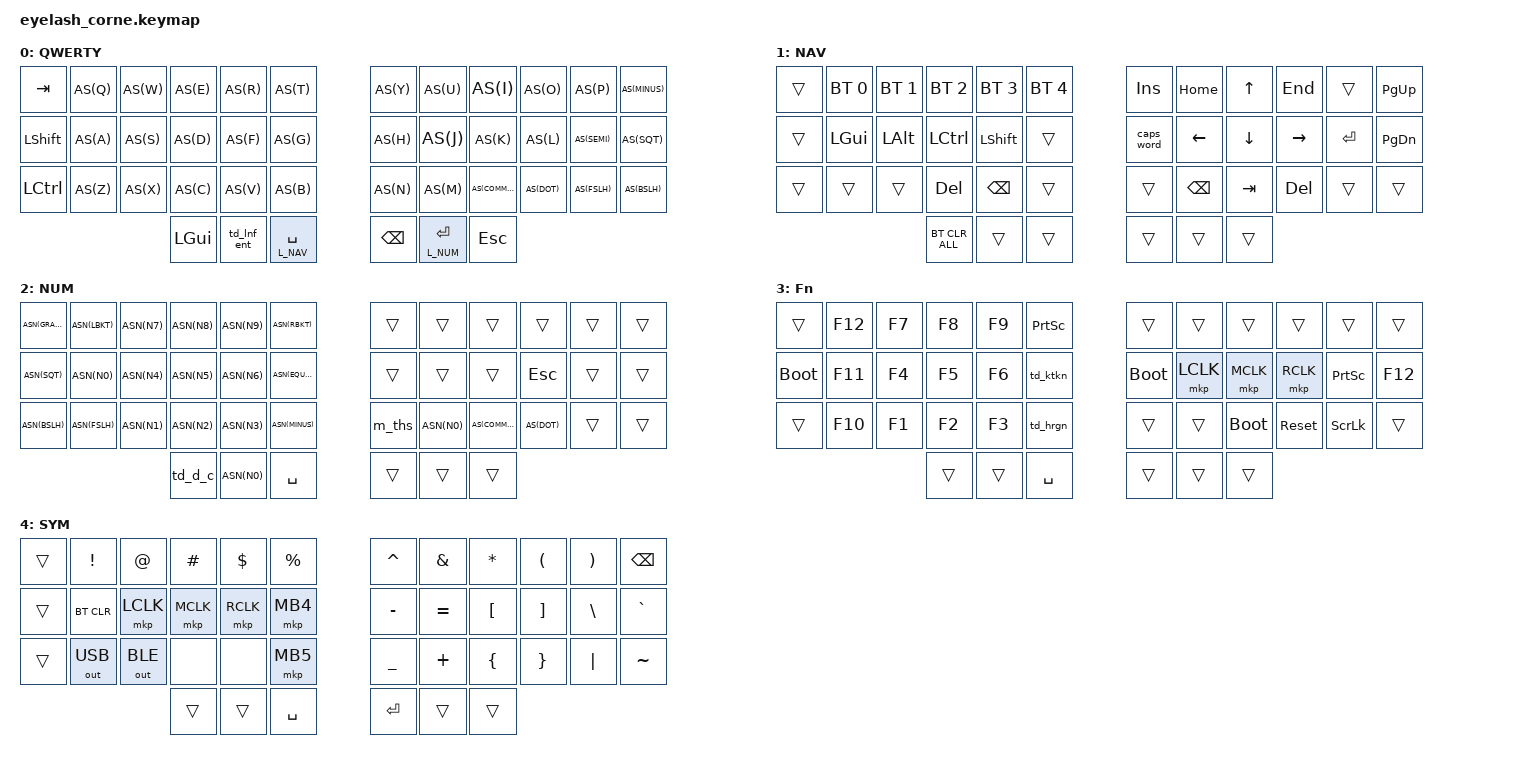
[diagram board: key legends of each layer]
#define ZMK_POINTING_DEFAULT_MOVE_VAL 1200  // 600
#define ZMK_POINTING_DEFAULT_SCRL_VAL 25   // 10

#include <input/processors.dtsi>
#include <zephyr/dt-bindings/input/input-event-codes.h>
#include <behaviors.dtsi>
#include <behaviors/runtime-sensor-rotate.dtsi>
#include <dt-bindings/zmk/bt.h>
#include <dt-bindings/zmk/keys.h>
#include <dt-bindings/zmk/outputs.h>
#include <dt-bindings/zmk/pointing.h>
#include <dt-bindings/zmk/rgb.h>

&soft_off { hold-time-ms = <2000>; };

// ------------ LAYERS -----------
#define L_DEFAULT 0
#define L_NAV 1
#define L_NUM 2
#define L_FUN 3

// -------- LAYER TOGGLES --------
#define LNAV_SPC &lt L_NAV SPACE
#define LNF_ENT &td_lnf_ent
#define LNUM_ENT &lt L_NUM ENTER

#define AS(keycode) &as LS(keycode) keycode     // Autoshift Macro
#define ASN(keycode) &as_ni LS(keycode) keycode   

// ------------ OTHERS -----------
#define MIC_TOGG &kp F24
#define CW_TOGG &caps_word

#define OUTUSB  &out OUT_USB
#define OUTBLE  &out OUT_BLE
#define BTCLR   &bt BT_CLR
#define BT_CLR_A &bt BT_CLR_ALL
#define BT_SEL_0 &bt BT_SEL 0
#define BT_SEL_1 &bt BT_SEL 1
#define BT_SEL_2 &bt BT_SEL 2
#define BT_SEL_3 &bt BT_SEL 3
#define BT_SEL_4 &bt BT_SEL 4

#define STD_UNL  &studio_unlock
#define BOOTLDER &bootloader
#define SYSRESET &sys_reset

/ {
    behaviors {
        as: auto_shift {
            compatible = "zmk,behavior-hold-tap";
            #binding-cells = <2>;
            tapping-term-ms = <250>;
            quick-tap-ms = <0>;
            require-prior-idle-ms = <50>;
            flavor = "tap-preferred";
            bindings = <&kp>, <&kp>;
        };
        // No prior idle is useful for preventing typos, but key presses
        // done after layer triggers have no need of prior idle.
        as_ni: auto_shift_no_idle {
            compatible = "zmk,behavior-hold-tap";
            #binding-cells = <2>;
            tapping-term-ms = <250>;
            quick-tap-ms = <0>;
            flavor = "tap-preferred";
            bindings = <&kp>, <&kp>;
        };
        lh: layer_tap_hold_preffered {
            compatible = "zmk,behavior-hold-tap";
            #binding-cells = <2>;
            tapping-term-ms = <200>;
            flavor = "hold-preferred";
            bindings = <&mo>, <&kp>;
        };
        td_d_c: tap_dance_dot_comma {
            compatible = "zmk,behavior-tap-dance";
            #binding-cells = <0>;
            tapping-term-ms = <250>;
            bindings = <&kp DOT>, <&kp COMMA>;
        };
        td_hrgn: tap_dance_hiragana {
            compatible = "zmk,behavior-tap-dance";
            #binding-cells = <0>;
            tapping-term-ms = <250>;
            bindings = <&kp LC(CAPS)>, <&kp LS(CAPS)>;
        };
        td_ktkn: tap_dance_katakana {
            compatible = "zmk,behavior-tap-dance";
            #binding-cells = <0>;
            tapping-term-ms = <250>;
            bindings = <&kp LA(CAPS)>, <&kp LS(CAPS)>;
        };
        td_lnf_ent: tap_dance_layer_num_fun_enter {
            compatible = "zmk,behavior-tap-dance";
            #binding-cells = <0>;
            tapping-term-ms = <200>;
            bindings = <&lh L_NUM ENTER>, <&mo L_FUN>;
        };
        
        rsr_vol: rsr_vol {
            compatible = "zmk,behavior-runtime-sensor-rotate";
            #sensor-binding-cells = <0>;
            tap-ms = <5>;
            cw-binding = <&kp C_VOL_UP>;
            ccw-binding = <&kp C_VOL_DN>;
        };

        rsr_trans: rsr_trans {
            compatible = "zmk,behavior-runtime-sensor-rotate";
            #sensor-binding-cells = <0>;
            tap-ms = <0>;
        };
    };

   combos {
        compatible = "zmk,combos";

        softoff {
            bindings = <&soft_off>;
            key-positions = <1 15 29>;
        };
    };

    macros {
        m_ths: m_ths {
            compatible = "zmk,behavior-macro";
            #binding-cells = <0>;
            bindings =
                <&kp N0>,
                <&kp N0>,
                <&kp N0>;
        };
    };
 
//  TODO: check if sensor binding is safe to remove
// also might be best to use the local compiler 
// then check for configs
// lastly, learn to use urob combos and home row
    keymap {
        compatible = "zmk,keymap";

        default_layer {
            display-name = "QWERTY";
            bindings = <
 &kp TAB   AS(Q)     AS(W)     AS(E)     AS(R)     AS(T)         AS(Y)     AS(U)     AS(I)     AS(O)     AS(P)     AS(MINUS)
 &kp LSHFT AS(A)     AS(S)     AS(D)     AS(F)     AS(G)         AS(H)     AS(J)     AS(K)     AS(L)     AS(SEMI)  AS(SQT) 
 &kp LCTRL AS(Z)     AS(X)     AS(C)     AS(V)     AS(B)         AS(N)     AS(M)     AS(COMMA) AS(DOT)   AS(FSLH)  AS(BSLH) 
                              &kp LGUI  LNF_ENT  LNAV_SPC        &kp BSPC  LNUM_ENT  &kp ESC
            >;

            sensor-bindings = <&rsr_vol &rsr_trans>;
        };

        navigation_layer {
            display-name = "NAV";
            bindings = <
&trans    BT_SEL_0  BT_SEL_1  BT_SEL_2  BT_SEL_3  BT_SEL_4       &kp INS  &kp HOME  &kp UP    &kp END   &trans    &kp PG_UP
&trans    &kp LGUI  &kp LALT  &kp LCTRL &kp LSHFT &trans         CW_TOGG  &kp LEFT  &kp DOWN  &kp RIGHT &kp ENTER &kp PG_DN
&trans    &trans    &trans    &kp DEL   &kp BSPC  &trans         &trans   &kp BSPC  &kp TAB   &kp DEL   &trans    &trans
                              BT_CLR_A  &trans    &trans         &trans   &trans    &trans
            >;
        };

        number_layer {
            display-name = "NUM";
            bindings = <   
ASN(GRAVE) ASN(LBKT) ASN(N7)   ASN(N8)   ASN(N9)   ASN(RBKT)     &trans   &trans   &trans    &trans    &trans     &trans
ASN(SQT)  ASN(N0)   ASN(N4)   ASN(N5)   ASN(N6)   ASN(EQUAL)     &trans   &trans   &trans    &kp ESC   &trans     &trans
ASN(BSLH) ASN(FSLH) ASN(N1)   ASN(N2)   ASN(N3)   ASN(MINUS)     &m_ths   ASN(N0)  AS(COMMA) AS(DOT)   &trans   &trans
                              &td_d_c   ASN(N0)   &kp SPACE      &trans   &trans   &trans
            >;

            sensor-bindings = <&rsr_vol &rsr_trans>;
        };

function_layer {
            display-name = "Fn";
            bindings = <
&trans    &kp F12   &kp F7    &kp F8    &kp F9    &kp PSCRN      &trans   &trans    &trans    &trans    &trans    &trans
BOOTLDER  &kp F11   &kp F4    &kp F5    &kp F6    &td_ktkn       BOOTLDER &mkp LCLK &mkp MCLK &mkp RCLK &kp PSCRN &kp F12
&trans    &kp F10   &kp F1    &kp F2    &kp F3    &td_hrgn       &trans   &trans    BOOTLDER  SYSRESET  &kp SLCK  &trans
                              &trans    &trans    &kp SPACE      &trans   &trans    &trans
            >;

            sensor-bindings = <&rsr_vol &rsr_trans>;
        };

        symbol_layer {
            display-name = "SYM";
            bindings = <
&trans    &kp EXCL  &kp AT    &kp HASH  &kp DLLR  &kp PRCNT      &kp CARET  &kp AMPS  &kp ASTRK &kp LPAR  &kp RPAR  &kp BSPC
&trans    BTCLR     &mkp LCLK &mkp MCLK &mkp RCLK &mkp MB4       &kp MINUS  &kp EQUAL &kp LBKT  &kp RBKT  &kp BSLH  &kp GRAVE
&trans    OUTUSB    OUTBLE    &none     &none     &mkp MB5       &kp UNDER  &kp PLUS  &kp LBRC  &kp RBRC  &kp PIPE  &kp TILDE
                              &trans    &trans    &kp SPACE      &kp RET    &trans    &trans
            >;

            sensor-bindings = <&rsr_vol &rsr_trans>;
        };

        
    };
};
